# PIC32MX695F512L register map
Registers are 32-bit, access not given, reset 0x0 unless marked. A register's access mark holds for its fields unless they carry their own. Offsets are from the block's base; [hi:lo] are bit positions; 'fields as' and 'values as' point back to an identical list.

## DMAC6 — DMAC6 peripheral
Base 0xBF8834E0
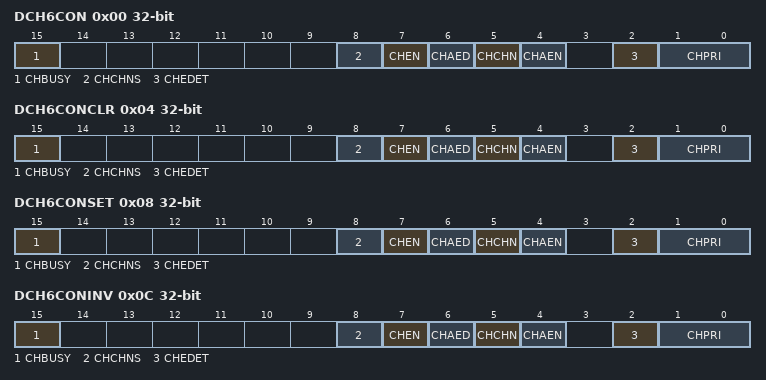
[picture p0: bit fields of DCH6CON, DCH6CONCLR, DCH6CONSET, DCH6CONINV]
0x00 DCH6CON
  [15] CHBUSY, [8] CHCHNS, [7] CHEN, [6] CHAED, [5] CHCHN, [4] CHAEN, [2] CHEDET, [1:0] CHPRI
0x04 DCH6CONCLR
  fields as DCH6CON
0x08 DCH6CONSET
  fields as DCH6CON
0x0C DCH6CONINV
  fields as DCH6CON
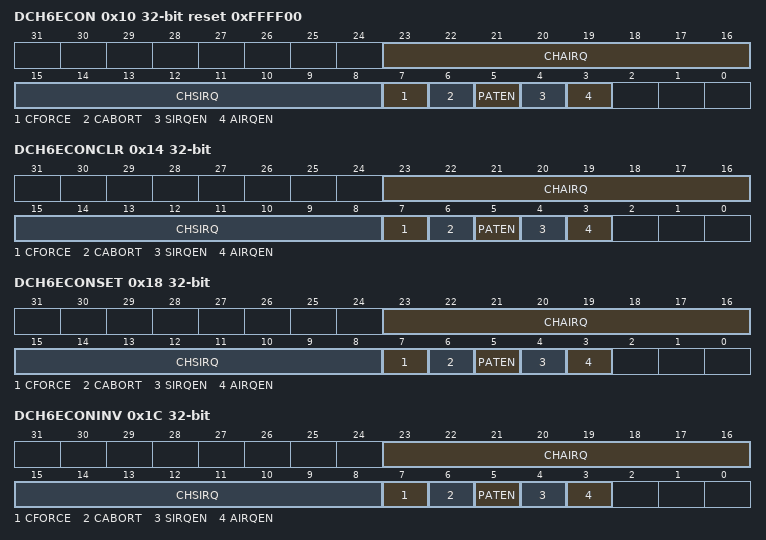
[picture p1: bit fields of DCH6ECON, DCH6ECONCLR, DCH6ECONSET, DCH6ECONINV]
0x10 DCH6ECON reset 0xFFFF00
  [23:16] CHAIRQ, [15:8] CHSIRQ, [7] CFORCE, [6] CABORT, [5] PATEN, [4] SIRQEN, [3] AIRQEN
0x14 DCH6ECONCLR
  fields as DCH6ECON
0x18 DCH6ECONSET
  fields as DCH6ECON
0x1C DCH6ECONINV
  fields as DCH6ECON
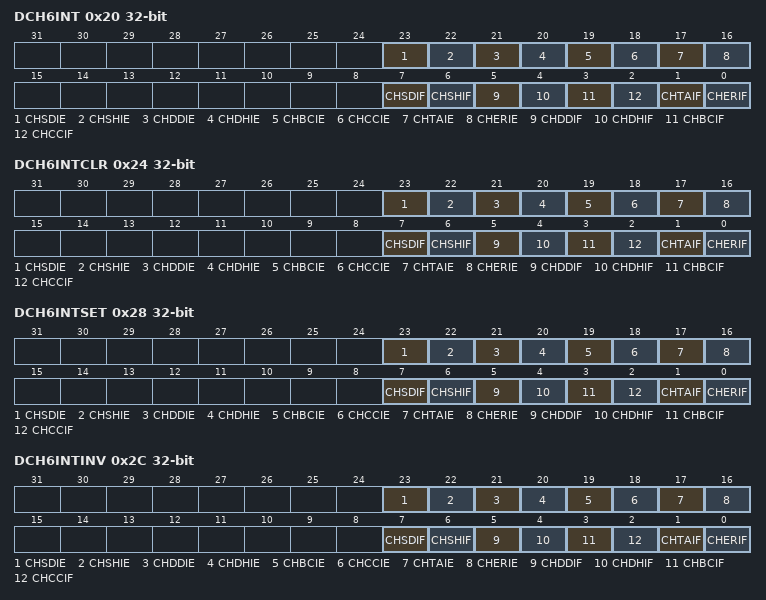
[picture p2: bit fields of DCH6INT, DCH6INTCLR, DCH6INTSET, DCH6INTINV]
0x20 DCH6INT
  [23] CHSDIE, [22] CHSHIE, [21] CHDDIE, [20] CHDHIE, [19] CHBCIE, [18] CHCCIE, [17] CHTAIE, [16] CHERIE, [7] CHSDIF, [6] CHSHIF, [5] CHDDIF, [4] CHDHIF, [3] CHBCIF, [2] CHCCIF, [1] CHTAIF, [0] CHERIF
0x24 DCH6INTCLR
  fields as DCH6INT
0x28 DCH6INTSET
  fields as DCH6INT
0x2C DCH6INTINV
  fields as DCH6INT
0x30 DCH6SSA
0x34 DCH6SSACLR
  [31:0] DCH6SSA
0x38 DCH6SSASET
  [31:0] DCH6SSA
0x3C DCH6SSAINV
  [31:0] DCH6SSA
0x40 DCH6DSA
0x44 DCH6DSACLR
  [31:0] DCH6DSA
0x48 DCH6DSASET
  [31:0] DCH6DSA
0x4C DCH6DSAINV
  [31:0] DCH6DSA
0x50 DCH6SSIZ
  [15:0] CHSSIZ
0x54 DCH6SSIZCLR
  [15:0] CHSSIZ
0x58 DCH6SSIZSET
  [15:0] CHSSIZ
0x5C DCH6SSIZINV
  [15:0] CHSSIZ
0x60 DCH6DSIZ
  [15:0] CHDSIZ
0x64 DCH6DSIZCLR
  [15:0] CHDSIZ
0x68 DCH6DSIZSET
  [15:0] CHDSIZ
0x6C DCH6DSIZINV
  [15:0] CHDSIZ
0x70 DCH6SPTR
  [15:0] CHSPTR
0x74 DCH6SPTRCLR
  [15:0] CHSPTR
0x78 DCH6SPTRSET
  [15:0] CHSPTR
0x7C DCH6SPTRINV
  [15:0] CHSPTR
0x80 DCH6DPTR
  [15:0] CHDPTR
0x84 DCH6DPTRCLR
  [15:0] CHDPTR
0x88 DCH6DPTRSET
  [15:0] CHDPTR
0x8C DCH6DPTRINV
  [15:0] CHDPTR
0x90 DCH6CSIZ
  [15:0] CHCSIZ
0x94 DCH6CSIZCLR
  [15:0] CHCSIZ
0x98 DCH6CSIZSET
  [15:0] CHCSIZ
0x9C DCH6CSIZINV
  [15:0] CHCSIZ
0xA0 DCH6CPTR
  [15:0] CHCPTR
0xA4 DCH6CPTRCLR
  [15:0] CHCPTR
0xA8 DCH6CPTRSET
  [15:0] CHCPTR
0xAC DCH6CPTRINV
  [15:0] CHCPTR
0xB0 DCH6DAT
  [7:0] DCHPDAT
0xB4 DCH6DATCLR
  [7:0] DCHPDAT
0xB8 DCH6DATSET
  [7:0] DCHPDAT
0xBC DCH6DATINV
  [7:0] DCHPDAT

## DMAC7 — DMAC7 peripheral
Base 0xBF8835A0
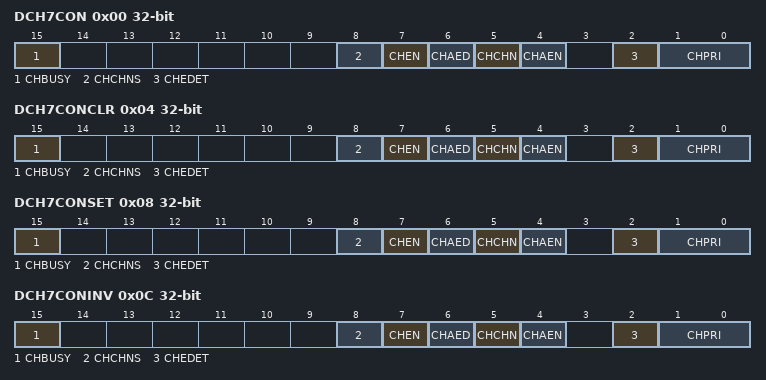
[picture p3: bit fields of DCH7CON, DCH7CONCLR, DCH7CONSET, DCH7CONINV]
0x00 DCH7CON
  [15] CHBUSY, [8] CHCHNS, [7] CHEN, [6] CHAED, [5] CHCHN, [4] CHAEN, [2] CHEDET, [1:0] CHPRI
0x04 DCH7CONCLR
  fields as DCH7CON
0x08 DCH7CONSET
  fields as DCH7CON
0x0C DCH7CONINV
  fields as DCH7CON
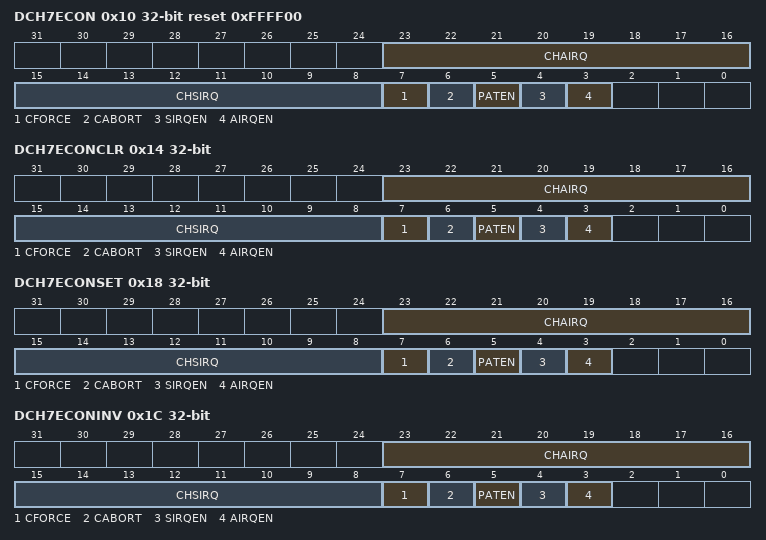
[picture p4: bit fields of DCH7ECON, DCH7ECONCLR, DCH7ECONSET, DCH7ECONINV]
0x10 DCH7ECON reset 0xFFFF00
  [23:16] CHAIRQ, [15:8] CHSIRQ, [7] CFORCE, [6] CABORT, [5] PATEN, [4] SIRQEN, [3] AIRQEN
0x14 DCH7ECONCLR
  fields as DCH7ECON
0x18 DCH7ECONSET
  fields as DCH7ECON
0x1C DCH7ECONINV
  fields as DCH7ECON
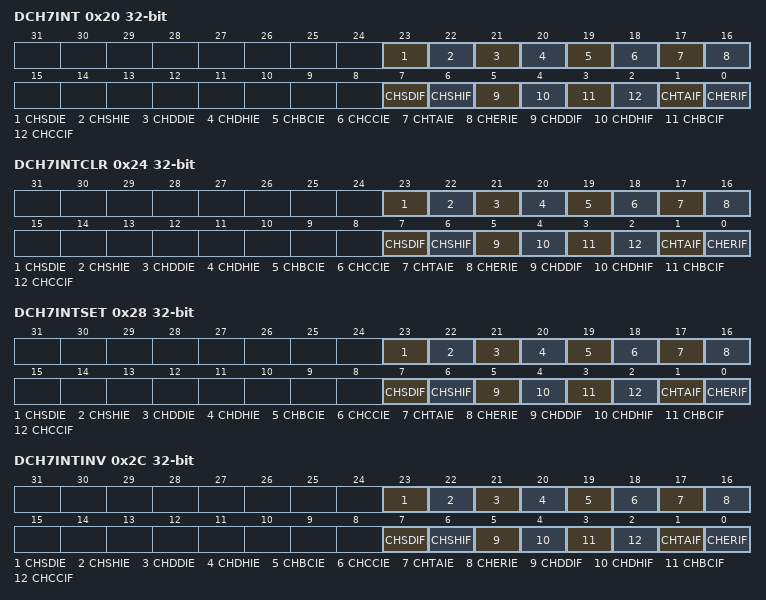
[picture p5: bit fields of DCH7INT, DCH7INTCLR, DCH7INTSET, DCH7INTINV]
0x20 DCH7INT
  [23] CHSDIE, [22] CHSHIE, [21] CHDDIE, [20] CHDHIE, [19] CHBCIE, [18] CHCCIE, [17] CHTAIE, [16] CHERIE, [7] CHSDIF, [6] CHSHIF, [5] CHDDIF, [4] CHDHIF, [3] CHBCIF, [2] CHCCIF, [1] CHTAIF, [0] CHERIF
0x24 DCH7INTCLR
  fields as DCH7INT
0x28 DCH7INTSET
  fields as DCH7INT
0x2C DCH7INTINV
  fields as DCH7INT
0x30 DCH7SSA
0x34 DCH7SSACLR
  [31:0] DCH7SSA
0x38 DCH7SSASET
  [31:0] DCH7SSA
0x3C DCH7SSAINV
  [31:0] DCH7SSA
0x40 DCH7DSA
0x44 DCH7DSACLR
  [31:0] DCH7DSA
0x48 DCH7DSASET
  [31:0] DCH7DSA
0x4C DCH7DSAINV
  [31:0] DCH7DSA
0x50 DCH7SSIZ
  [15:0] CHSSIZ
0x54 DCH7SSIZCLR
  [15:0] CHSSIZ
0x58 DCH7SSIZSET
  [15:0] CHSSIZ
0x5C DCH7SSIZINV
  [15:0] CHSSIZ
0x60 DCH7DSIZ
  [15:0] CHDSIZ
0x64 DCH7DSIZCLR
  [15:0] CHDSIZ
0x68 DCH7DSIZSET
  [15:0] CHDSIZ
0x6C DCH7DSIZINV
  [15:0] CHDSIZ
0x70 DCH7SPTR
  [15:0] CHSPTR
0x74 DCH7SPTRCLR
  [15:0] CHSPTR
0x78 DCH7SPTRSET
  [15:0] CHSPTR
0x7C DCH7SPTRINV
  [15:0] CHSPTR
0x80 DCH7DPTR
  [15:0] CHDPTR
0x84 DCH7DPTRCLR
  [15:0] CHDPTR
0x88 DCH7DPTRSET
  [15:0] CHDPTR
0x8C DCH7DPTRINV
  [15:0] CHDPTR
0x90 DCH7CSIZ
  [15:0] CHCSIZ
0x94 DCH7CSIZCLR
  [15:0] CHCSIZ
0x98 DCH7CSIZSET
  [15:0] CHCSIZ
0x9C DCH7CSIZINV
  [15:0] CHCSIZ
0xA0 DCH7CPTR
  [15:0] CHCPTR
0xA4 DCH7CPTRCLR
  [15:0] CHCPTR
0xA8 DCH7CPTRSET
  [15:0] CHCPTR
0xAC DCH7CPTRINV
  [15:0] CHCPTR
0xB0 DCH7DAT
  [7:0] DCHPDAT
0xB4 DCH7DATCLR
  [7:0] DCHPDAT
0xB8 DCH7DATSET
  [7:0] DCHPDAT
0xBC DCH7DATINV
  [7:0] DCHPDAT
